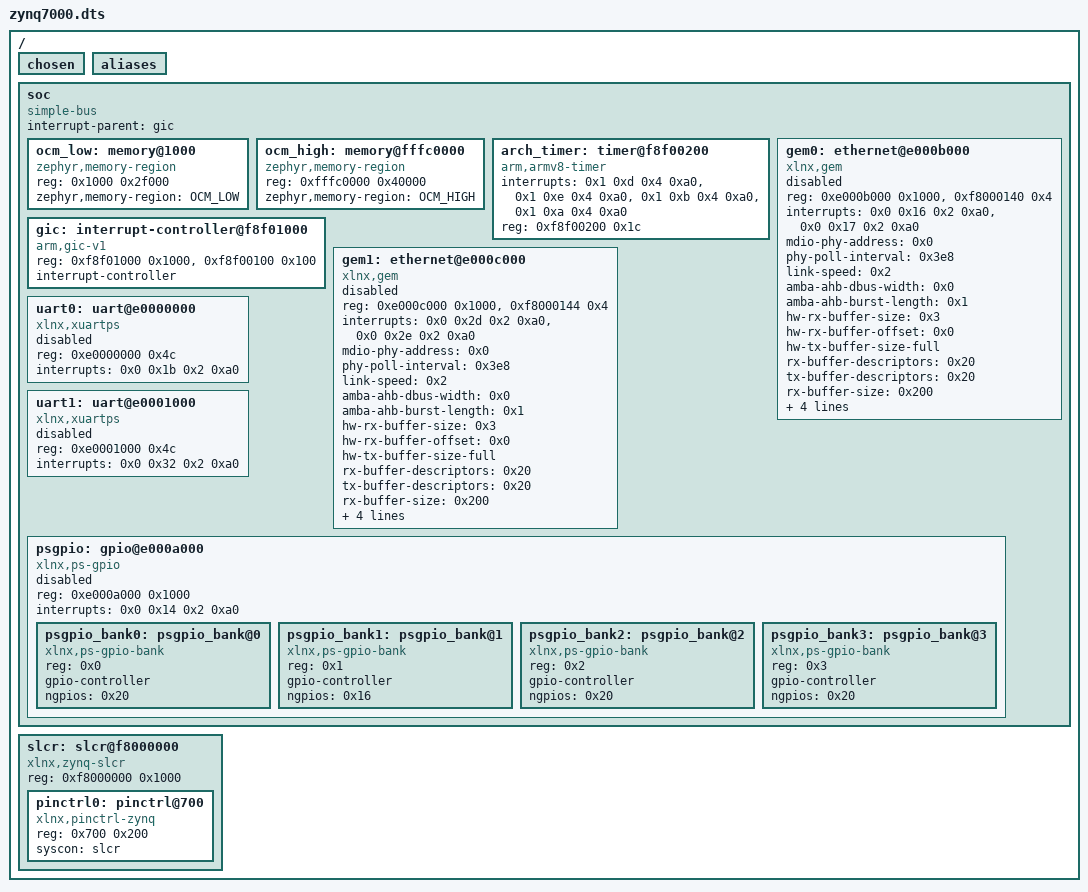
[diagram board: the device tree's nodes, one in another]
/dts-v1/;

/ {
	#address-cells = < 0x1 >;
	#size-cells = < 0x1 >;
	chosen {
	};
	aliases {
	};
	soc {
		#address-cells = < 0x1 >;
		#size-cells = < 0x1 >;
		compatible = "simple-bus";
		ranges;
		interrupt-parent = < &gic >;
		ocm_low: memory@1000 {
			compatible = "zephyr,memory-region", "xlnx,zynq-ocm";
			reg = < 0x1000 0x2f000 >;
			zephyr,memory-region = "OCM_LOW";
		};
		ocm_high: memory@fffc0000 {
			compatible = "zephyr,memory-region", "xlnx,zynq-ocm";
			reg = < 0xfffc0000 0x40000 >;
			zephyr,memory-region = "OCM_HIGH";
		};
		arch_timer: timer@f8f00200 {
			compatible = "arm,armv8-timer";
			status = "okay";
			interrupt-names = "irq_0", "irq_1", "irq_2", "irq_3";
			interrupts = < 0x1 0xd 0x4 0xa0 >, < 0x1 0xe 0x4 0xa0 >, < 0x1 0xb 0x4 0xa0 >, < 0x1 0xa 0x4 0xa0 >;
			reg = < 0xf8f00200 0x1c >;
		};
		gic: interrupt-controller@f8f01000 {
			compatible = "arm,gic-v1", "arm,gic";
			status = "okay";
			reg = < 0xf8f01000 0x1000 >, < 0xf8f00100 0x100 >;
			interrupt-controller;
			#interrupt-cells = < 0x4 >;
			phandle = < 0x1 >;
		};
		gem0: ethernet@e000b000 {
			compatible = "xlnx,gem";
			status = "disabled";
			reg = < 0xe000b000 0x1000 >, < 0xf8000140 0x4 >;
			interrupts = < 0x0 0x16 0x2 0xa0 >, < 0x0 0x17 0x2 0xa0 >;
			interrupt-names = "irq_0", "irq_1";
			mdio-phy-address = < 0x0 >;
			phy-poll-interval = < 0x3e8 >;
			link-speed = < 0x2 >;
			amba-ahb-dbus-width = < 0x0 >;
			amba-ahb-burst-length = < 0x1 >;
			hw-rx-buffer-size = < 0x3 >;
			hw-rx-buffer-offset = < 0x0 >;
			hw-tx-buffer-size-full;
			rx-buffer-descriptors = < 0x20 >;
			tx-buffer-descriptors = < 0x20 >;
			rx-buffer-size = < 0x200 >;
			tx-buffer-size = < 0x200 >;
			discard-rx-fcs;
			unicast-hash;
			full-duplex;
		};
		gem1: ethernet@e000c000 {
			compatible = "xlnx,gem";
			status = "disabled";
			reg = < 0xe000c000 0x1000 >, < 0xf8000144 0x4 >;
			interrupts = < 0x0 0x2d 0x2 0xa0 >, < 0x0 0x2e 0x2 0xa0 >;
			interrupt-names = "irq_0", "irq_1";
			mdio-phy-address = < 0x0 >;
			phy-poll-interval = < 0x3e8 >;
			link-speed = < 0x2 >;
			amba-ahb-dbus-width = < 0x0 >;
			amba-ahb-burst-length = < 0x1 >;
			hw-rx-buffer-size = < 0x3 >;
			hw-rx-buffer-offset = < 0x0 >;
			hw-tx-buffer-size-full;
			rx-buffer-descriptors = < 0x20 >;
			tx-buffer-descriptors = < 0x20 >;
			rx-buffer-size = < 0x200 >;
			tx-buffer-size = < 0x200 >;
			discard-rx-fcs;
			unicast-hash;
			full-duplex;
		};
		uart0: uart@e0000000 {
			compatible = "xlnx,xuartps";
			status = "disabled";
			reg = < 0xe0000000 0x4c >;
			interrupts = < 0x0 0x1b 0x2 0xa0 >;
			interrupt-names = "irq_0";
		};
		uart1: uart@e0001000 {
			compatible = "xlnx,xuartps";
			status = "disabled";
			reg = < 0xe0001000 0x4c >;
			interrupts = < 0x0 0x32 0x2 0xa0 >;
			interrupt-names = "irq_0";
		};
		psgpio: gpio@e000a000 {
			compatible = "xlnx,ps-gpio";
			status = "disabled";
			reg = < 0xe000a000 0x1000 >;
			interrupts = < 0x0 0x14 0x2 0xa0 >;
			interrupt-names = "irq_0";
			#address-cells = < 0x1 >;
			#size-cells = < 0x0 >;
			psgpio_bank0: psgpio_bank@0 {
				compatible = "xlnx,ps-gpio-bank";
				reg = < 0x0 >;
				gpio-controller;
				#gpio-cells = < 0x2 >;
				ngpios = < 0x20 >;
				status = "okay";
			};
			psgpio_bank1: psgpio_bank@1 {
				compatible = "xlnx,ps-gpio-bank";
				reg = < 0x1 >;
				gpio-controller;
				#gpio-cells = < 0x2 >;
				ngpios = < 0x16 >;
				status = "okay";
			};
			psgpio_bank2: psgpio_bank@2 {
				compatible = "xlnx,ps-gpio-bank";
				reg = < 0x2 >;
				gpio-controller;
				#gpio-cells = < 0x2 >;
				ngpios = < 0x20 >;
				status = "okay";
			};
			psgpio_bank3: psgpio_bank@3 {
				compatible = "xlnx,ps-gpio-bank";
				reg = < 0x3 >;
				gpio-controller;
				#gpio-cells = < 0x2 >;
				ngpios = < 0x20 >;
				status = "okay";
			};
		};
	};
	slcr: slcr@f8000000 {
		#address-cells = < 0x1 >;
		#size-cells = < 0x1 >;
		compatible = "xlnx,zynq-slcr", "syscon";
		reg = < 0xf8000000 0x1000 >;
		ranges;
		phandle = < 0x2 >;
		pinctrl0: pinctrl@700 {
			compatible = "xlnx,pinctrl-zynq";
			reg = < 0x700 0x200 >;
			syscon = < &slcr >;
		};
	};
};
